AUTOSAR XML (schema 4-3-0)
package /Impl_SWC_TPMS_APS_ARPkg
  swc implementation Impl_SWC_TPMS_APS_type: programming-language=C, sw-version=1.0.0, vendor-id=0, behavior=SWC_TPMS_APS_type_IB
    code-descriptors:
      code SRC: artifact-descriptors=autosar-engineering-object={short-label=EngObject, category=SWSRC}
    resource consumption ResourceConsumption
      memory section Mem_SWC_TPMS_APS_CAL: size=0, sw-addrmethod=CAL, symbol=CAL
      memory section Mem_SWC_TPMS_APS_CODE: size=0, sw-addrmethod=CODE, symbol=CODE
package /Impl_Type_TPMS_APS_ARPkg
  7 x impl type:
    DT_TPMS_APS_outputs: category=STRUCTURE
      32 x element, all with category=TYPE_REFERENCE:
        u16Array4_ApsInDist: implementation-data-type=u16_APSArray4_type
        u8Array12_ApsInUssSta: implementation-data-type=u8_USSArray12_type
        u8Array8_ApsInLevel: implementation-data-type=u8_APSLevelArray8_type
        u8Array8_PasInDist: implementation-data-type=u8_PASArray8_type
        u8Array9_TPMSData: implementation-data-type=u8_TPMSDataArray9_type
        u8_ApsInPASChime: implementation-data-type=uint8
        u8_ApsInSensorLayout: implementation-data-type=uint8
        u8_ApsInSysFailSta: implementation-data-type=uint8
        u8_ApsInSysMode: implementation-data-type=uint8
        u8_TPMSDataInSta: implementation-data-type=uint8
        u8_GetAPS_Progress_PCT: implementation-data-type=uint8
        u8_GetAPS_RQ_Display: implementation-data-type=uint8
        u8_GetAPS_SW_Ver: implementation-data-type=uint8
        u8_GetAPS_HW_Ver: implementation-data-type=uint8
        u8_GetAPS_ExitCondition: implementation-data-type=uint8
        f32_GetAPS_Angle_Target: implementation-data-type=float32
        u8_GetAPS_Sta_System: implementation-data-type=uint8
        u8_GetAPS_V_Rq_EPAS_Ctrl: implementation-data-type=uint8
        u8_GetAPS_Rq_EPAS_Ctrl: implementation-data-type=uint8
        u8_GetAPS_Req: implementation-data-type=uint8
        f32_GetAPS_DecReq: implementation-data-type=float32
        u8_GetAPS_DecReq_A: implementation-data-type=uint8
        f32_GetAPS_SpeedCmd: implementation-data-type=float32
        u8_GetAPS_ShftPosnReq: implementation-data-type=uint8
        u8_GetAPS_VMC_Req_A: implementation-data-type=uint8
        u8_GetCAAS_Sta: implementation-data-type=uint8
        u8_GetCAAS_VMC_Req_A: implementation-data-type=uint8
        u8_GetAPS_PwrReq_cmd: implementation-data-type=uint8
        u8_GetRAPS_BCM_LockReq_Cmd: implementation-data-type=uint8
        u8_GetRAPS_BCM_Lamp_Cmd: implementation-data-type=uint8
        u8_GetRAPS_ErrWarn_Sta: implementation-data-type=uint8
        u8_GetRAPS_ErrLv1_flg: implementation-data-type=uint8
    u16_APSArray4_type: category=ARRAY
      element u16_ApsElement: category=VALUE, array-size=4, array-size-semantics=FIXED-SIZE, base-type=uint16
    u8_APSLevelArray8_type: category=ARRAY
      element u8_APSLevelElement: category=VALUE, array-size=8, array-size-semantics=FIXED-SIZE, base-type=uint8
    u8_PASArray8_type: category=ARRAY
      element u8_PasElement: category=VALUE, array-size=8, array-size-semantics=FIXED-SIZE, base-type=uint8
    u8_USSArray12_type: category=ARRAY
      element u8_UssElement: category=VALUE, array-size=12, array-size-semantics=FIXED-SIZE, base-type=uint8
    u8_TPMSDataArray9_type: category=ARRAY
      element u8TPMSDataElement: category=VALUE, array-size=9, array-size-semantics=FIXED-SIZE, base-type=uint8
    u8Array2_TPMSSensorIDRegResults_type: category=ARRAY
      element u8_Element: category=VALUE, array-size=2, array-size-semantics=FIXED-SIZE, base-type=uint8
package /Interface_TPMS_APS_ARPkg
  sender receiver interface IF_BTPMS_APS_outputs
    data BTPMS_APS_outputs: type=DT_TPMS_APS_outputs
  client server interface IF_HALIN_APS
    8 x operation:
      CSOP_ApsGetData
        22 x arg, all with direction=OUT, server-argument-impl-policy=USE-ARGUMENT-TYPE:
          u8_GetAPS_Progress_PCT: type=uint8
          u8_GetAPS_RQ_Display: type=uint8
          u8_GetAPS_SW_Ver: type=uint8
          u8_GetAPS_HW_Ver: type=uint8
          u8_GetAPS_ExitCondition: type=uint8
          f32_GetAPS_Angle_Target: type=float32
          u8_GetAPS_Sta_System: type=uint8
          u8_GetAPS_V_Rq_EPAS_Ctrl: type=uint8
          u8_GetAPS_Rq_EPAS_Ctrl: type=uint8
          u8_GetAPS_Req: type=uint8
          f32_GetAPS_DecReq: type=float32
          u8_GetAPS_DecReq_A: type=uint8
          f32_GetAPS_SpeedCmd: type=float32
          u8_GetAPS_ShftPosnReq: type=uint8
          u8_GetAPS_VMC_Req_A: type=uint8
          u8_GetCAAS_Sta: type=uint8
          u8_GetCAAS_VMC_Req_A: type=uint8
          u8_GetAPS_PwrReq_cmd: type=uint8
          u8_GetRAPS_BCM_LockReq_Cmd: type=uint8
          u8_GetRAPS_BCM_Lamp_Cmd: type=uint8
          u8_GetRAPS_ErrWarn_Sta: type=uint8
          u8_GetRAPS_ErrLv1_flg: type=uint8
      CSOP_ApsGetDist
        arg u8Array8_PasInDist: type=u8_PASArray8_type, direction=OUT, server-argument-impl-policy=USE-ARGUMENT-TYPE
        arg u16Array4_ApsInDist: type=u16_APSArray4_type, direction=OUT, server-argument-impl-policy=USE-ARGUMENT-TYPE
      CSOP_ApsGetDistLevel
        arg u8Array8_ApsInLevel: type=u8_APSLevelArray8_type, direction=OUT, server-argument-impl-policy=USE-ARGUMENT-TYPE
      CSOP_ApsGetOtherStatus
        4 x arg, all with type=uint8, direction=OUT, server-argument-impl-policy=USE-ARGUMENT-TYPE:
          u8_ApsInPASChime
          u8_ApsInSensorLayout
          u8_ApsInSysFailSta
          u8_ApsInSysMode
      CSOP_ApsGetUssSta
        arg u8Array12_ApsInUssSta: type=u8_USSArray12_type, direction=OUT, server-argument-impl-policy=USE-ARGUMENT-TYPE
      CSOP_TPMS_GetRawData
        arg u8_TPMSDataInSta: type=uint8, direction=OUT, server-argument-impl-policy=USE-ARGUMENT-TYPE
        arg u8Array9_TPMSData: type=u8_TPMSDataArray9_type, direction=OUT, server-argument-impl-policy=USE-ARGUMENT-TYPE
      CSOP_PAS_Handler
      CSOP_TPMS_Handler
  client server interface IF_HALOUT_APS
    operation CSOP_ApsOutput
      6 x arg, all with direction=IN, server-argument-impl-policy=USE-ARGUMENT-TYPE:
        f32_ApsOutVehSpdSig: type=float32
        u8_ApsOutGearPosnSig: type=uint8
        u8_ApsOutSetFrSensorOnCmd: type=uint8
        u8_ApsOutSetVehSpdTOCmd: type=uint8
        u8_ApsOutSetFrSensorSwTOCmd: type=uint8
        u8_ApsOutSendChrgPlugSta: type=uint8
    operation CSOP_ApsSetData
      83 x arg, all with direction=IN, server-argument-impl-policy=USE-ARGUMENT-TYPE:
        u8_SetPwrSta: type=uint8
        f32_SetBrkPedalPos: type=float32
        f32_SetActAPSPosn: type=float32
        f32_SetLF_RawWhlSpeed: type=float32
        f32_SetRF_RawWhlSpeed: type=float32
        f32_SetLR_RawWhlSpeed: type=float32
        f32_SetRR_RawWhlSpeed: type=float32
        u8_SetLF_RawWhlSpeed_V: type=uint8
        u8_SetRF_RawWhlSpeed_V: type=uint8
        u8_SetLR_RawWhlSpeed_V: type=uint8
        u8_SetRR_RawWhlSpeed_V: type=uint8
        u8_SetLF_WhlRotDir: type=uint8
        u8_SetRF_WhlRotDir: type=uint8
        u8_SetLR_WhlRotDir: type=uint8
        u8_SetRR_WhlRotDir: type=uint8
        u8_SetLF_PulseCount_V: type=uint8
        u8_SetRF_PulseCount_V: type=uint8
        u8_SetLR_PulseCount_V: type=uint8
        u8_SetRR_PulseCount_V: type=uint8
        s16_SetLF_PulseCount: type=sint16
        s16_SetRF_PulseCount: type=sint16
        s16_SetLR_PulseCount: type=sint16
        s16_SetRR_PulseCount: type=sint16
        u8_SetAPS_Active: type=uint8
        u8_SetAPS_CtrlAvail: type=uint8
        u8_SetShifter_Handle_Cmd: type=uint8
        u8_SetDriIntend: type=uint8
        u8_SetEPS_AOI_Control: type=uint8
        f32_SetSAS_Angle: type=float32
        f32_SetSAS_Speed: type=float32
        u8_SetSAS_Speed_Valid: type=uint8
        u8_SetSAS_CAL: type=uint8
        u8_SetSAS_OK: type=uint8
        f32_SetGRADE: type=float32
        f32_SetYawRate: type=float32
        f32_SetLatAccel: type=float32
        f32_SetLongAccel: type=float32
        f32_SetMCPressure: type=float32
        u8_SetYawRate_V: type=uint8
        u8_SetLatAccel_V: type=uint8
        u8_SetLongAccel_V: type=uint8
        u8_SetMCPressure_V: type=uint8
        u8_SetBrkSw_Sta: type=uint8
        u8_SetBrkSw_V: type=uint8
        u8_SetESC_Standstill: type=uint8
        u8_SetESC_APS_Sta: type=uint8
        u8_SetEPBExtReleaseAvail: type=uint8
        u8_SetEPBExtApplyAvail: type=uint8
        u8_SetEPBErrSta: type=uint8
        u8_SetEPBSta: type=uint8
        u8_SetAllDoorSW: type=uint8
        u8_SetHoodSW: type=uint8
        u8_SetTailgate_SW: type=uint8
        u8_SetAVM_parking_cancel: type=uint8
        u8_SetAVM_parking_excute: type=uint8
        u8_SetAVM_Parking_mode: type=uint8
        u8_SetAVM_Err_STA: type=uint8
        u8_SetIVI_Status: type=uint8
        u8_SetCAAS_Sw: type=uint8
        u8_SetIVI_Screen: type=uint8
        u8_SetCAAS_CtrlAvail: type=uint8
        u8_SetABS_Active: type=uint8
        u8_SetTCS_Active: type=uint8
        u8_SetDriverSeatBeltCmd: type=uint8
        u8_SetDrDoorSW: type=uint8
        u8_SetPsDoorSW: type=uint8
        u8_SetRLDoorSW: type=uint8
        u8_SetRRDoorSW: type=uint8
        u8_SetRFPressIndi: type=uint8
        u8_SetLFPressIndi: type=uint8
        u8_SetRRPressIndi: type=uint8
        u8_SetLRPressIndi: type=uint8
        f32_SetsigAmbAirT: type=float32
        f32_SetVehActSpd: type=float32
        u8_SetCAAS_Active: type=uint8
        u8_SetAPS_PwrReqAvail_sta: type=uint8
        u8_SetDKC_PDkeyAreaRAPS_Sta: type=uint8
        u8_SetDKC_ParkingMode_Cmd: type=uint8
        u8_SetP_UID_LowPower: type=uint8
        u8_SetDr_SeatSta: type=uint8
        u8_SetVCU_RAPSErrLv2_flg: type=uint8
        u8_SetVCU_RAPSErrLv3_flg: type=uint8
        u8_SetIVI_UserTakeOver_APS_Sta: type=uint8
    operation CSOP_ApsSetTimeout
      69 x arg, all with type=uint8, direction=IN, server-argument-impl-policy=USE-ARGUMENT-TYPE:
        u8_SetBrkPedalPosTO
        u8_SetLF_RawWhlSpeedTO
        u8_SetRF_RawWhlSpeedTO
        u8_SetLR_RawWhlSpeedTO
        u8_SetRR_RawWhlSpeedTO
        u8_SetLF_RawWhlSpeed_VTO
        u8_SetRF_RawWhlSpeed_VTO
        u8_SetLR_RawWhlSpeed_VTO
        u8_SetRR_RawWhlSpeed_VTO
        u8_SetLF_WhlRotDirTO
        u8_SetRF_WhlRotDirTO
        u8_SetLR_WhlRotDirTO
        u8_SetRR_WhlRotDirTO
        u8_SetLF_PulseCount_VTO
        u8_SetRF_PulseCount_VTO
        u8_SetLR_PulseCount_VTO
        u8_SetRR_PulseCount_VTO
        u8_SetLF_PulseCountTO
        u8_SetRF_PulseCountTO
        u8_SetLR_PulseCountTO
        u8_SetRR_PulseCountTO
        u8_SetShifter_Handle_CmdTO
        u8_SetDriIntendTO
        u8_SetEPS_AOI_ControlTO
        u8_SetSAS_AngleTO
        u8_SetSAS_SpeedTO
        u8_SetSAS_Speed_ValidTO
        u8_SetSAS_CALTO
        u8_SetSAS_OKTO
        u8_SetGRADETO
        u8_SetYawRateTO
        u8_SetLatAccelTO
        u8_SetLongAccelTO
        u8_SetMCPressureTO
        u8_SetYawRate_VTO
        u8_SetLatAccel_VTO
        u8_SetLongAccel_VTO
        u8_SetMCPressure_VTO
        u8_SetBrkSw_StaTO
        u8_SetBrkSw_VTO
        u8_SetESC_StandstillTO
        u8_SetESC_APS_StaTO
        u8_SetEPBExtReleaseAvailTO
        u8_SetEPBExtApplyAvailTO
        u8_SetEPBErrStaTO
        u8_SetEPBStaTO
        u8_SetAVM_parking_cancelTO
        u8_SetAVM_parking_excuteTO
        u8_SetAVM_Parking_modeTO
        u8_SetAVM_Err_STATO
        u8_SetIVI_StatusTO
        u8_SetCAAS_SwTO
        u8_SetIVI_ScreenTO
        u8_SetABS_ActiveTO
        u8_SetTCS_ActiveTO
        u8_SetDriverSeatBeltCmdTO
        u8_SetRFPressIndiTO
        u8_SetLFPressIndiTO
        u8_SetRRPressIndiTO
        u8_SetLRPressIndiTO
        u8_SetsigAmbAirTTO
        u8_SetAPS_PwrReqAvail_staTO
        u8_SetDKC_PDkeyAreaRAPS_StaTO
        u8_SetDKC_ParkingMode_CmdTO
        u8_SetP_UID_LowPowerTO
        u8_SetDr_SeatStaTO
        u8_SetVCU_RAPSErrLv2_flgTO
        u8_SetVCU_RAPSErrLv3_flgTO
        u8_SetIVI_UserTakeOver_APS_StaTO
package /SWC_TPMS_APS_ARPkg
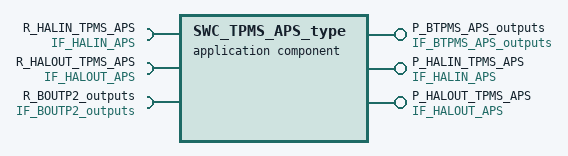
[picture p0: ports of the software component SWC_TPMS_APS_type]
  application sw component type SWC_TPMS_APS_type
    provide port P_BTPMS_APS_outputs: provided-interface=IF_BTPMS_APS_outputs
    provide port P_HALIN_TPMS_APS: provided-interface=IF_HALIN_APS
    provide port P_HALOUT_TPMS_APS: provided-interface=IF_HALOUT_APS
    require port R_HALIN_TPMS_APS: required-interface=IF_HALIN_APS
    require port R_HALOUT_TPMS_APS: required-interface=IF_HALOUT_APS
    require port R_BOUTP2_outputs: required-interface=IF_BOUTP2_outputs
    behavior SWC_TPMS_APS_type_IB: data-type-mapping=AppModeTypeMap, handle-termination-and-restart=NO-SUPPORT
      4 x timing event:
        TE_TPMS_APS_5ms: start-on-event=run_SWC_TPMS_APS_5ms, period=0.005
        TE_TPMS_APS_10ms: start-on-event=run_SWC_TPMS_APS_10ms, period=0.01
        TE_PAS_1ms: start-on-event=run_SWC_HALOUT_PAS_1ms, period=0.001
        TE_TPMS_10ms: start-on-event=run_SWC_HALOUT_TPMS_10ms, period=0.01
      11 x operation invoked event:
        oie_P_HALIN_TPMS_APS_CSOP_ApsGetData: start-on-event=run_HALINAPS_ApsGetData, operation=P_HALIN_TPMS_APS.CSOP_ApsGetData
        oie_P_HALIN_TPMS_APS_CSOP_ApsGetDist: start-on-event=run_HALINAPS_ApsGetDist, operation=P_HALIN_TPMS_APS.CSOP_ApsGetDist
        oie_P_HALIN_TPMS_APS_CSOP_ApsGetDistLevel: start-on-event=run_HALINAPS_ApsGetDistLevel, operation=P_HALIN_TPMS_APS.CSOP_ApsGetDistLevel
        oie_P_HALIN_TPMS_APS_CSOP_ApsGetOtherStatus: start-on-event=run_HALINAPS_GetApsOtherStatus, operation=P_HALIN_TPMS_APS.CSOP_ApsGetOtherStatus
        oie_P_HALIN_TPMS_APS_CSOP_ApsGetUssSta: start-on-event=run_HALINAPS_ApsGetUssSta, operation=P_HALIN_TPMS_APS.CSOP_ApsGetUssSta
        oie_P_HALOUT_TPMS_APS_CSOP_ApsOutput: start-on-event=run_HALOUTAPS_ApsOutput, operation=P_HALOUT_TPMS_APS.CSOP_ApsOutput
        oie_P_HALOUT_TPMS_APS_CSOP_ApsSetData: start-on-event=run_HALOUTAPS_ApsSetData, operation=P_HALOUT_TPMS_APS.CSOP_ApsSetData
        oie_P_HALOUT_TPMS_APS_CSOP_ApsSetTimeout: start-on-event=run_HALOUTAPS_ApsSetTimeout, operation=P_HALOUT_TPMS_APS.CSOP_ApsSetTimeout
        oie_P_HALIN_CSOP_TPMS_GetRawData: start-on-event=run_HALINCDD_TPMS_GetRawData, operation=P_HALIN_TPMS_APS.CSOP_TPMS_GetRawData
        oie_P_HALIN_CSOP_PAS_Handler: start-on-event=run_PAS_Handler, operation=P_HALIN_TPMS_APS.CSOP_PAS_Handler
        oie_P_HALIN_CSOP_TPMS_Handler: start-on-event=run_TPMS_Handler, operation=P_HALIN_TPMS_APS.CSOP_TPMS_Handler
      explicit-inter-runnable-variables:
        16 x data:
          IRV_u16Array4_ApsInDist: type=u16_APSArray4_type
          IRV_u8Array12_ApsInUssSta: type=u8_USSArray12_type
          IRV_u8Array8_ApsInLevel: type=u8_APSLevelArray8_type
          IRV_u8Array8_PasInDist: type=u8_PASArray8_type
          IRV_u8Array9_TPMSData: type=u8_TPMSDataArray9_type
          IRV_u8_ApsInPASChime: type=uint8
          IRV_u8_ApsInSensorLayout: type=uint8
          IRV_u8_ApsInSysFailSta: type=uint8
          IRV_u8_ApsInSysMode: type=uint8
          IRV_u8_TPMSDataInSta: type=uint8
          IRV_f32_ApsOutVehSpdSig: type=float32
          IRV_u8_ApsOutGearPosnSig: type=uint8
          IRV_u8_ApsOutSendChrgPlugSta: type=uint8
          IRV_u8_ApsOutSetFrSensorOnCmd: type=uint8
          IRV_u8_ApsOutSetFrSensorSwTOCmd: type=uint8
          IRV_u8_ApsOutSetVehSpdTOCmd: type=uint8
      15 x runnable:
        run_SWC_TPMS_APS_5ms
          data-receive-point-by-arguments:
            access drparg_BOUTP2_outputs: accessed-variable=R_BOUTP2_outputs.BOUTP2_outputs
          data-send-points:
            access dsp_BTPMS_APS_outputs: accessed-variable=P_BTPMS_APS_outputs.BTPMS_APS_outputs
          read-local-variables:
            10 x access:
              IRV_u16Array4_ApsInDist: accessed-variable=IRV_u16Array4_ApsInDist
              IRV_u8Array12_ApsInUssSta: accessed-variable=IRV_u8Array12_ApsInUssSta
              IRV_u8Array8_ApsInLevel: accessed-variable=IRV_u8Array8_ApsInLevel
              IRV_u8Array8_PasInDist: accessed-variable=IRV_u8Array8_PasInDist
              IRV_u8Array9_TPMSData: accessed-variable=IRV_u8Array9_TPMSData
              IRV_u8_ApsInPASChime: accessed-variable=IRV_u8_ApsInPASChime
              IRV_u8_ApsInSensorLayout: accessed-variable=IRV_u8_ApsInSensorLayout
              IRV_u8_ApsInSysFailSta: accessed-variable=IRV_u8_ApsInSysFailSta
              IRV_u8_ApsInSysMode: accessed-variable=IRV_u8_ApsInSysMode
              IRV_u8_TPMSDataInSta: accessed-variable=IRV_u8_TPMSDataInSta
          sync call scp_CSOP_ApsGetData: operation=R_HALIN_TPMS_APS.CSOP_ApsGetData, timeout=0.0
          sync call scp_CSOP_ApsSetData: operation=R_HALOUT_TPMS_APS.CSOP_ApsSetData, timeout=0.0
          sync call scp_CSOP_ApsSetTimeout: operation=R_HALOUT_TPMS_APS.CSOP_ApsSetTimeout, timeout=0.0
          written-local-variables:
            6 x access:
              IRV_f32_ApsOutVehSpdSig: accessed-variable=IRV_f32_ApsOutVehSpdSig
              IRV_u8_ApsOutGearPosnSig: accessed-variable=IRV_u8_ApsOutGearPosnSig
              IRV_u8_ApsOutSendChrgPlugSta: accessed-variable=IRV_u8_ApsOutSendChrgPlugSta
              IRV_u8_ApsOutSetFrSensorOnCmd: accessed-variable=IRV_u8_ApsOutSetFrSensorOnCmd
              IRV_u8_ApsOutSetFrSensorSwTOCmd: accessed-variable=IRV_u8_ApsOutSetFrSensorSwTOCmd
              IRV_u8_ApsOutSetVehSpdTOCmd: accessed-variable=IRV_u8_ApsOutSetVehSpdTOCmd
        run_SWC_TPMS_APS_10ms
          read-local-variables:
            6 x access:
              IRV_f32_ApsOutVehSpdSig: accessed-variable=IRV_f32_ApsOutVehSpdSig
              IRV_u8_ApsOutGearPosnSig: accessed-variable=IRV_u8_ApsOutGearPosnSig
              IRV_u8_ApsOutSendChrgPlugSta: accessed-variable=IRV_u8_ApsOutSendChrgPlugSta
              IRV_u8_ApsOutSetFrSensorOnCmd: accessed-variable=IRV_u8_ApsOutSetFrSensorOnCmd
              IRV_u8_ApsOutSetFrSensorSwTOCmd: accessed-variable=IRV_u8_ApsOutSetFrSensorSwTOCmd
              IRV_u8_ApsOutSetVehSpdTOCmd: accessed-variable=IRV_u8_ApsOutSetVehSpdTOCmd
          6 x sync call, all with timeout=0.0:
            scp_CSOP_ApsGetDist: operation=R_HALIN_TPMS_APS.CSOP_ApsGetDist
            scp_CSOP_ApsGetDistLevel: operation=R_HALIN_TPMS_APS.CSOP_ApsGetDistLevel
            scp_CSOP_ApsGetUssSta: operation=R_HALIN_TPMS_APS.CSOP_ApsGetUssSta
            scp_CSOP_GetAPSOtherStatus: operation=R_HALIN_TPMS_APS.CSOP_ApsGetOtherStatus
            scp_CSOP_TPMS_GetRawData: operation=R_HALIN_TPMS_APS.CSOP_TPMS_GetRawData
            scp_CSOP_ApsOutput: operation=R_HALOUT_TPMS_APS.CSOP_ApsOutput
          written-local-variables:
            10 x access:
              IRV_u16Array4_ApsInDist: accessed-variable=IRV_u16Array4_ApsInDist
              IRV_u8Array12_ApsInUssSta: accessed-variable=IRV_u8Array12_ApsInUssSta
              IRV_u8Array8_ApsInLevel: accessed-variable=IRV_u8Array8_ApsInLevel
              IRV_u8Array8_PasInDist: accessed-variable=IRV_u8Array8_PasInDist
              IRV_u8Array9_TPMSData: accessed-variable=IRV_u8Array9_TPMSData
              IRV_u8_ApsInPASChime: accessed-variable=IRV_u8_ApsInPASChime
              IRV_u8_ApsInSensorLayout: accessed-variable=IRV_u8_ApsInSensorLayout
              IRV_u8_ApsInSysFailSta: accessed-variable=IRV_u8_ApsInSysFailSta
              IRV_u8_ApsInSysMode: accessed-variable=IRV_u8_ApsInSysMode
              IRV_u8_TPMSDataInSta: accessed-variable=IRV_u8_TPMSDataInSta
        run_HALINAPS_ApsGetData
        run_HALINAPS_ApsGetDist
        run_HALINAPS_ApsGetDistLevel
        run_HALINAPS_ApsGetUssSta
        run_HALINAPS_GetApsOtherStatus
        run_HALOUTAPS_ApsOutput
        run_HALOUTAPS_ApsSetData
        run_HALOUTAPS_ApsSetTimeout
        run_HALINCDD_TPMS_GetRawData
        run_SWC_HALOUT_PAS_1ms
          sync call scp_CSOP_PAS_Handler: operation=R_HALIN_TPMS_APS.CSOP_PAS_Handler, timeout=0.0
        run_SWC_HALOUT_TPMS_10ms
          sync call scp_CSOP_TPMS_Handler: operation=R_HALIN_TPMS_APS.CSOP_TPMS_Handler, timeout=0.0
        run_PAS_Handler
        run_TPMS_Handler
